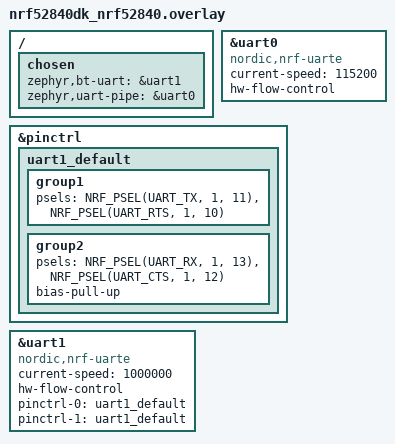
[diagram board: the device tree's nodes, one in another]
/* SPDX-License-Identifier: Apache-2.0 */

/ {
	chosen {
		/delete-property/ zephyr,console;
		/delete-property/ zephyr,shell-uart;
		zephyr,bt-uart = &uart1;
		zephyr,uart-pipe = &uart0;
	};
};

&uart0 {
	compatible = "nordic,nrf-uarte";
	current-speed = <115200>;
	status = "okay";
	hw-flow-control;
};

&pinctrl {
	uart1_default {
		group1 {
			psels =
			<NRF_PSEL(UART_TX, 1, 11)>,
			<NRF_PSEL(UART_RTS, 1, 10)>;
		};
		group2 {
			psels =
			<NRF_PSEL(UART_RX, 1, 13)>,
			<NRF_PSEL(UART_CTS, 1, 12)>;
			bias-pull-up;
		};
	};
};

&uart1 {
	status = "okay";
	compatible = "nordic,nrf-uarte";
	current-speed = <1000000>;
	hw-flow-control;
	pinctrl-0 = <&uart1_default>;
	pinctrl-1 = <&uart1_default>;
};
